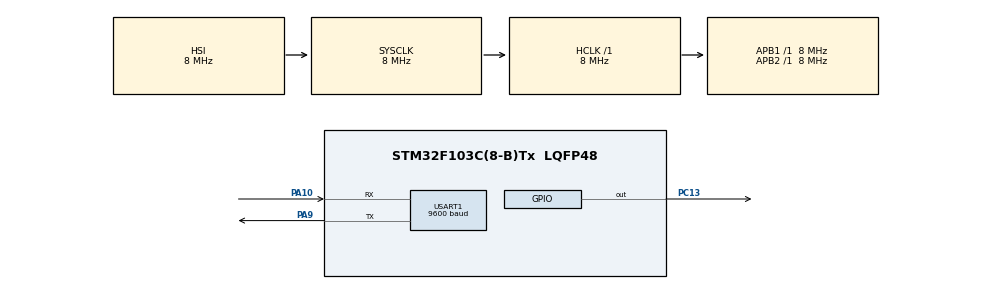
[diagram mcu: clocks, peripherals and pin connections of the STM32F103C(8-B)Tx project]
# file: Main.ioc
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Mcu.Family=STM32F1
Mcu.Name=STM32F103C(8-B)Tx
Mcu.Package=LQFP48
NVIC.PriorityGroup=NVIC_PRIORITYGROUP_4
NVIC.RTC_IRQn=true\:0\:0\:false\:false\:true\:true\:true\:true
PA10.Mode=Asynchronous
PA10.Signal=USART1_RX
PA13.Mode=JTAG_4_pins
PA13.Signal=SYS_JTMS-SWDIO
PA14.Mode=JTAG_4_pins
PA14.Signal=SYS_JTCK-SWCLK
PA15.Mode=JTAG_4_pins
PA15.Signal=SYS_JTDI
PA9.Mode=Asynchronous
PA9.Signal=USART1_TX
PB3.Mode=JTAG_4_pins
PB3.Signal=SYS_JTDO-TRACESWO
PC13-TAMPER-RTC.PinState=GPIO_PIN_SET
PC13-TAMPER-RTC.Signal=GPIO_Output
PC14-OSC32_IN.Mode=LSE-External-Oscillator
PC14-OSC32_IN.Signal=RCC_OSC32_IN
PC15-OSC32_OUT.Mode=LSE-External-Oscillator
PC15-OSC32_OUT.Signal=RCC_OSC32_OUT
ProjectManager.HeapSize=0x200
ProjectManager.StackSize=0x400
ProjectManager.TargetToolchain=MDK-ARM V5.32
RCC.AHBFreq_Value=8000000
RCC.APB1Freq_Value=8000000
RCC.APB1TimFreq_Value=8000000
RCC.APB2Freq_Value=8000000
RCC.APB2TimFreq_Value=8000000
RCC.HCLKFreq_Value=8000000
RCC.PLLMUL=RCC_PLL_MUL9
RCC.RTCClockSelection=RCC_RTCCLKSOURCE_LSE
RCC.SYSCLKFreq_VALUE=8000000
RCC.USBFreq_Value=36000000
RTC.AutoPrediv=RTC_AUTO_1_SECOND
RTC.Format=RTC_FORMAT_BIN
RTC.OutPut=RTC_OUTPUTSOURCE_NONE
USART1.BaudRate=9600
USART1.VirtualMode=VM_ASYNC
VP_RTC_No_RTC_Output.Mode=RTC_OUT_NO
VP_RTC_VS_RTC_Activate.Mode=RTC_Enabled
board=custom

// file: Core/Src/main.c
/* USER CODE BEGIN Header */
/**
  ******************************************************************************
  * @file           : main.c
  * @brief          : Main program body
  ******************************************************************************
  * @attention
  *
  * Copyright (c) 2026 STMicroelectronics.
  * All rights reserved.
  *
  * This software is licensed under terms that can be found in the LICENSE file
  * in the root directory of this software component.
  * If no LICENSE file comes with this software, it is provided AS-IS.
  *
  ******************************************************************************
  */
/* USER CODE END Header */
#include "main.h"

RTC_HandleTypeDef hrtc;

UART_HandleTypeDef huart1;

/* USER CODE BEGIN PV */
volatile uint8_t rtc_sec_flag = 0;
volatile uint8_t rtc_alarm_flag = 0;
/* USER CODE END PV */

void SystemClock_Config(void);
static void MX_GPIO_Init(void);
static void MX_RTC_Init(void);
static void MX_USART1_UART_Init(void);
/* USER CODE BEGIN PFP */
static void UART_TransmitString(UART_HandleTypeDef *huart, const char *str);
/* USER CODE END PFP */

int main(void)
{

  /* USER CODE BEGIN 1 */
  uint32_t led_on_tick = 0;
  RTC_TimeTypeDef sTime = {0};
  RTC_AlarmTypeDef sAlarm = {0};
  /* USER CODE END 1 */

  /* MCU Configuration--------------------------------------------------------*/

  /* Reset of all peripherals, Initializes the Flash interface and the Systick. */
  HAL_Init();

  /* Configure the system clock */
  SystemClock_Config();

  /* Initialize all configured peripherals */
  MX_GPIO_Init();
  MX_RTC_Init();
  MX_USART1_UART_Init();
  /* USER CODE BEGIN 2 */
	sAlarm.Alarm = RTC_ALARM_A;
	sAlarm.AlarmTime.Hours = 0;
	sAlarm.AlarmTime.Minutes = 0;
	sAlarm.AlarmTime.Seconds = 10;
	HAL_RTC_SetAlarm_IT(&hrtc, &sAlarm, RTC_FORMAT_BIN);

	HAL_RTCEx_SetSecond_IT(&hrtc);
  /* USER CODE END 2 */

  /* Infinite loop */
  /* USER CODE BEGIN WHILE */
	UART_TransmitString(&huart1, "RTC TEST \r");

  while (1)
  {
    /* USER CODE END WHILE */

    /* USER CODE BEGIN 3 */
		if(rtc_sec_flag == 1){
			rtc_sec_flag = 0;
			HAL_GPIO_WritePin(GPIOC, GPIO_PIN_13, GPIO_PIN_RESET);
			led_on_tick = HAL_GetTick();
		}
		if(led_on_tick > 0){
			if((HAL_GetTick() - led_on_tick) >= 100){
				HAL_GPIO_WritePin(GPIOC, GPIO_PIN_13, GPIO_PIN_SET);
				led_on_tick = 0;
			}
		}

    if(rtc_alarm_flag == 1){
			rtc_alarm_flag = 0;
      HAL_RTC_GetTime(&hrtc, &sTime, RTC_FORMAT_BIN);

      uint32_t total = (sTime.Hours * 3600U) + (sTime.Minutes * 60U) + sTime.Seconds;
      total += 10U;
      total %= (24U * 3600U);

      sAlarm.Alarm = RTC_ALARM_A;
      sAlarm.AlarmTime.Hours   = total / 3600U;
      sAlarm.AlarmTime.Minutes = (total % 3600U) / 60U;
      sAlarm.AlarmTime.Seconds = total % 60U;
      HAL_RTC_SetAlarm_IT(&hrtc, &sAlarm, RTC_FORMAT_BIN);

      UART_TransmitString(&huart1, "RTC ALARM !!!\r");
    }
  }
  /* USER CODE END 3 */
}

void SystemClock_Config(void)
{
  RCC_OscInitTypeDef RCC_OscInitStruct = {0};
  RCC_ClkInitTypeDef RCC_ClkInitStruct = {0};
  RCC_PeriphCLKInitTypeDef PeriphClkInit = {0};

  /** Initializes the RCC Oscillators according to the specified parameters
  * in the RCC_OscInitTypeDef structure.
  */
  RCC_OscInitStruct.OscillatorType = RCC_OSCILLATORTYPE_HSI|RCC_OSCILLATORTYPE_LSE;
  RCC_OscInitStruct.LSEState = RCC_LSE_ON;
  RCC_OscInitStruct.HSIState = RCC_HSI_ON;
  RCC_OscInitStruct.HSICalibrationValue = RCC_HSICALIBRATION_DEFAULT;
  RCC_OscInitStruct.PLL.PLLState = RCC_PLL_NONE;
  if (HAL_RCC_OscConfig(&RCC_OscInitStruct) != HAL_OK)
  {
    Error_Handler();
  }

  /** Initializes the CPU, AHB and APB buses clocks
  */
  RCC_ClkInitStruct.ClockType = RCC_CLOCKTYPE_HCLK|RCC_CLOCKTYPE_SYSCLK
                              |RCC_CLOCKTYPE_PCLK1|RCC_CLOCKTYPE_PCLK2;
  RCC_ClkInitStruct.SYSCLKSource = RCC_SYSCLKSOURCE_HSI;
  RCC_ClkInitStruct.AHBCLKDivider = RCC_SYSCLK_DIV1;
  RCC_ClkInitStruct.APB1CLKDivider = RCC_HCLK_DIV1;
  RCC_ClkInitStruct.APB2CLKDivider = RCC_HCLK_DIV1;

  if (HAL_RCC_ClockConfig(&RCC_ClkInitStruct, FLASH_LATENCY_0) != HAL_OK)
  {
    Error_Handler();
  }
  PeriphClkInit.PeriphClockSelection = RCC_PERIPHCLK_RTC;
  PeriphClkInit.RTCClockSelection = RCC_RTCCLKSOURCE_LSE;
  if (HAL_RCCEx_PeriphCLKConfig(&PeriphClkInit) != HAL_OK)
  {
    Error_Handler();
  }
}

static void MX_RTC_Init(void)
{

  RTC_TimeTypeDef sTime = {0};
  RTC_DateTypeDef DateToUpdate = {0};

  /** Initialize RTC Only
  */
  hrtc.Instance = RTC;
  hrtc.Init.AsynchPrediv = RTC_AUTO_1_SECOND;
  hrtc.Init.OutPut = RTC_OUTPUTSOURCE_NONE;
  if (HAL_RTC_Init(&hrtc) != HAL_OK)
  {
    Error_Handler();
  }

  /** Initialize RTC and set the Time and Date
  */
  sTime.Hours = 0;
  sTime.Minutes = 0;
  sTime.Seconds = 0;

  if (HAL_RTC_SetTime(&hrtc, &sTime, RTC_FORMAT_BIN) != HAL_OK)
  {
    Error_Handler();
  }
  DateToUpdate.WeekDay = RTC_WEEKDAY_MONDAY;
  DateToUpdate.Month = RTC_MONTH_JANUARY;
  DateToUpdate.Date = 1;
  DateToUpdate.Year = 0;

  if (HAL_RTC_SetDate(&hrtc, &DateToUpdate, RTC_FORMAT_BIN) != HAL_OK)
  {
    Error_Handler();
  }

}

static void MX_USART1_UART_Init(void)
{

  huart1.Instance = USART1;
  huart1.Init.BaudRate = 9600;
  huart1.Init.WordLength = UART_WORDLENGTH_8B;
  huart1.Init.StopBits = UART_STOPBITS_1;
  huart1.Init.Parity = UART_PARITY_NONE;
  huart1.Init.Mode = UART_MODE_TX_RX;
  huart1.Init.HwFlowCtl = UART_HWCONTROL_NONE;
  huart1.Init.OverSampling = UART_OVERSAMPLING_16;
  if (HAL_UART_Init(&huart1) != HAL_OK)
  {
    Error_Handler();
  }

}

static void MX_GPIO_Init(void)
{
  GPIO_InitTypeDef GPIO_InitStruct = {0};

  /* GPIO Ports Clock Enable */
  __HAL_RCC_GPIOC_CLK_ENABLE();
  __HAL_RCC_GPIOA_CLK_ENABLE();
  __HAL_RCC_GPIOB_CLK_ENABLE();

  /*Configure GPIO pin Output Level */
  HAL_GPIO_WritePin(GPIOC, GPIO_PIN_13, GPIO_PIN_SET);

  /*Configure GPIO pin : PC13 */
  GPIO_InitStruct.Pin = GPIO_PIN_13;
  GPIO_InitStruct.Mode = GPIO_MODE_OUTPUT_PP;
  GPIO_InitStruct.Pull = GPIO_NOPULL;
  GPIO_InitStruct.Speed = GPIO_SPEED_FREQ_LOW;
  HAL_GPIO_Init(GPIOC, &GPIO_InitStruct);

}

/* USER CODE BEGIN 4 */
static void UART_TransmitString(UART_HandleTypeDef *huart, const char *str){
  uint16_t len = 0;
  while(str[len] != 0){
    len++;
  }
  HAL_UART_Transmit(huart, (uint8_t*)str, len, HAL_MAX_DELAY);
}

void HAL_RTCEx_RTCEventCallback(RTC_HandleTypeDef *hrtc){
  rtc_sec_flag = 1;
}

void HAL_RTC_AlarmAEventCallback(RTC_HandleTypeDef *hrtc){
  rtc_alarm_flag = 1;
}
/* USER CODE END 4 */

void Error_Handler(void)
{
  __disable_irq();
  while (1)
  {
  }
}
